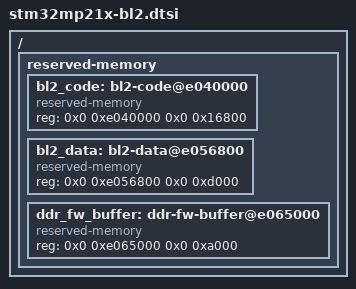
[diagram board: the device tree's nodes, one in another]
// SPDX-License-Identifier: (GPL-2.0-only OR BSD-3-Clause)
/*
 * Copyright (C) STMicroelectronics 2024 - All Rights Reserved
 * Author: Loic Pallardy loic.pallardy@foss.st.com for STMicroelectronics.
 */

/ {
	reserved-memory {
		#address-cells = <2>;
		#size-cells = <2>;
		ranges;

		bl2_code: bl2-code@e040000 {
			compatible = "reserved-memory";
			reg = <0x0 0xe040000 0x0 0x16800>;
			#memory-region-cells = <0>;
		};

		bl2_data: bl2-data@e056800 {
			compatible = "reserved-memory";
			reg = <0x0 0xe056800 0x0 0xd000>;
			#memory-region-cells = <0>;
		};

		ddr_fw_buffer: ddr-fw-buffer@e065000 {
			compatible = "reserved-memory";
			reg = <0x0 0xe065000 0x0 0xa000>;
			#memory-region-cells = <0>;
		};
	};
};
